# STM32U575 register map
File version: 1.4
CPU: CM33 r0p1, little endian, MPU, FPU, 4 interrupt priority bits
Registers are 32-bit, read-write, reset 0x0 unless marked. A register's access mark holds for its fields unless they carry their own. Offsets are from the block's base; [hi:lo] are bit positions; {n}, {i} and the like mark numbered series; 'fields as' and 'values as' point back to an identical list.

## FMC
Base 0x420D0400
Same registers: SEC_FMC 0x520D0400
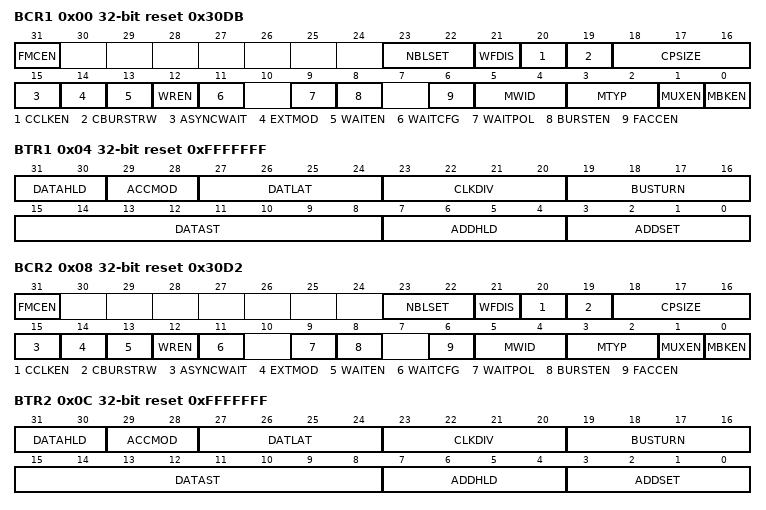
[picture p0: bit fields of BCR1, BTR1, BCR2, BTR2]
0x00 BCR1 reset 0x30DB — SRAM/NOR-Flash chip-select control register for bank 1
  [31] FMCEN — FMC controller enable
  [23:22] NBLSET — Byte lane (NBL) setup
  [21] WFDIS — Write FIFO disable
  [20] CCLKEN — Continuous clock enable
  [19] CBURSTRW — Write burst enable
  [18:16] CPSIZE — CRAM Page Size
  [15] ASYNCWAIT — Wait signal during asynchronous transfers
  [14] EXTMOD — Extended mode enable
  [13] WAITEN — Wait enable bit
  [12] WREN — Write enable bit
  [11] WAITCFG — Wait timing configuration
  [9] WAITPOL — Wait signal polarity bit
  [8] BURSTEN — Burst enable bit
  [6] FACCEN — Flash access enable
  [5:4] MWID — Memory data bus width
  [3:2] MTYP — Memory type
  [1] MUXEN — Address/data multiplexing enable bit
  [0] MBKEN — Memory bank enable bit
0x04 BTR1 reset 0xFFFFFFF — SRAM/NOR-Flash chip-select timing register for bank 1
  [31:30] DATAHLD — Data hold phase duration
  [29:28] ACCMOD — Access mode
  [27:24] DATLAT — Data latency for synchronous memory
  [23:20] CLKDIV — Clock divide ratio (for FMC_CLK signal)
  [19:16] BUSTURN — Bus turnaround phase duration
  [15:8] DATAST — Data-phase duration
  [7:4] ADDHLD — Address-hold phase duration
  [3:0] ADDSET — Address setup phase duration
0x08 BCR2 reset 0x30D2 — SRAM/NOR-Flash chip-select control register for bank 2
  fields as BCR1
0x0C BTR2 reset 0xFFFFFFF — SRAM/NOR-Flash chip-select timing register for bank 2
  fields as BTR1
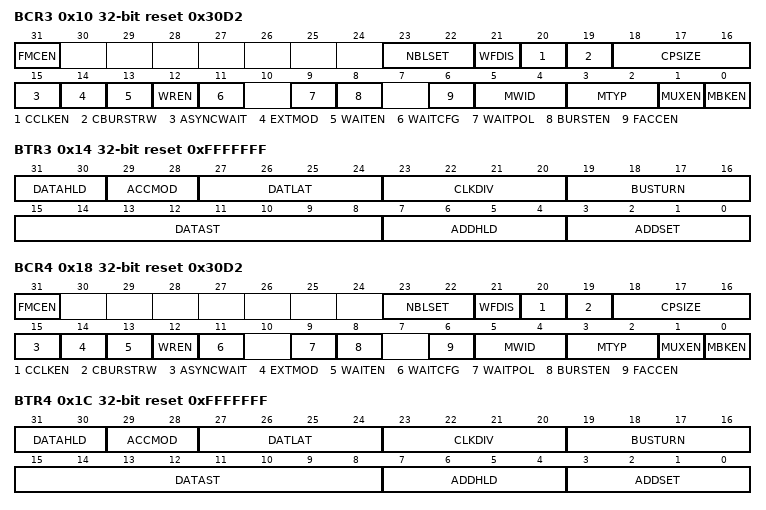
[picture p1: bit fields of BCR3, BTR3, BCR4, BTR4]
0x10 BCR3 reset 0x30D2 — SRAM/NOR-Flash chip-select control register for bank 3
  fields as BCR1
0x14 BTR3 reset 0xFFFFFFF — SRAM/NOR-Flash chip-select timing register for bank 3
  fields as BTR1
0x18 BCR4 reset 0x30D2 — SRAM/NOR-Flash chip-select control register for bank 4
  fields as BCR1
0x1C BTR4 reset 0xFFFFFFF — SRAM/NOR-Flash chip-select timing register for bank 4
  fields as BTR1
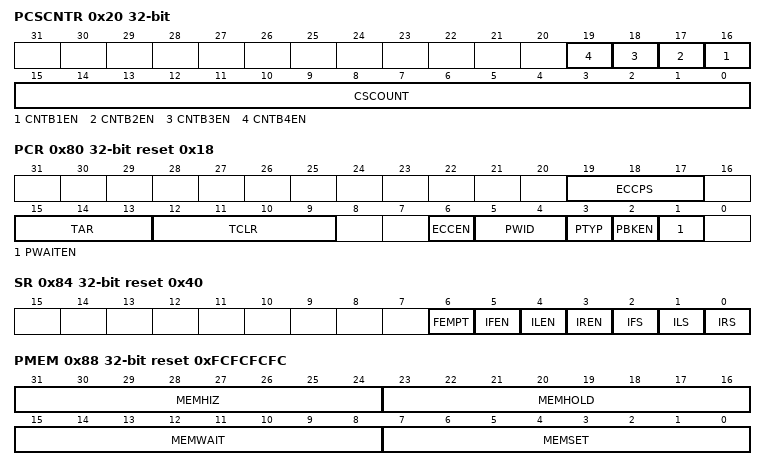
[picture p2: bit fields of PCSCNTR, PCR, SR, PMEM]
0x20 PCSCNTR — PSRAM chip select counter register
  [n+15] CNTB{n}EN (n=1..4) — Counter Bank {n} enable
  [15:0] CSCOUNT — Chip select counter
0x80 PCR reset 0x18 — NAND Flash control registers
  [19:17] ECCPS — ECC page size
  [15:13] TAR — ALE to RE delay
  [12:9] TCLR — CLE to RE delay
  [6] ECCEN — ECC computation logic enable bit
  [5:4] PWID — Data bus width
  [3] PTYP — Memory type
  [2] PBKEN — NAND Flash memory bank enable bit
  [1] PWAITEN — Wait feature enable bit
0x84 SR access per field reset 0x40 — status and interrupt register
  [6] FEMPT ro — FIFO empty. Read-only bit that provides the status of the FIFO
  [5] IFEN rw — Interrupt falling edge detection enable bit
  [4] ILEN rw — Interrupt high-level detection enable bit
  [3] IREN rw — Interrupt rising edge detection enable bit
  [2] IFS rw — Interrupt falling edge status The flag is set by hardware and reset by software. Note: If this bit is written by software to 1 it will be set.
  [1] ILS rw — Interrupt high-level status The flag is set by hardware and reset by software.
  [0] IRS rw — Interrupt rising edge status The flag is set by hardware and reset by software. Note: If this bit is written by software to 1 it will be set.
0x88 PMEM reset 0xFCFCFCFC — Common memory space timing register
  [31:24] MEMHIZ — Common memory x data bus Hi-Z time These bits define the number of KCK_FMC clock cycles during which the data bus is kept Hi-Z after the start of a NAND Flash write access to common memory space. This is only valid for write transactions:
  [23:16] MEMHOLD — Common memory hold time These bits define the number of KCK_FMC clock cycles for write accesses and KCK_FMC+1 clock cycles for read accesses during which the address is held (and data for write accesses) after the command is de-asserted (NWE, NOE), for NAND Flash read or write access to common memory space:
  [15:8] MEMWAIT — Common memory wait time These bits define the minimum number of KCK_FMC (+1) clock cycles to assert the command (NWE, NOE), for NAND Flash read or write access to common memory space. The duration of command assertion is extended if the wait signal (NWAIT) is active (low) at the end of the programmed value of KCK_FMC:
  [7:0] MEMSET — Common memory x setup time These bits define the number of KCK_FMC (+1) clock cycles to set up the address before the command assertion (NWE, NOE), for NAND Flash read or write access to common memory space:
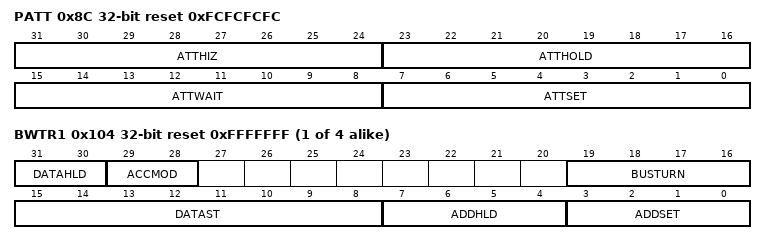
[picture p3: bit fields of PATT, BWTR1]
0x8C PATT reset 0xFCFCFCFC — The FMC_PATT read/write register contains the timing information for NAND Flash memory bank. It is used for 8-bit accesses to the attribute memory space of the NAND Flash for the last address write access if the timing must differ from that of previous accesses (for Ready/Busy management, refer to Section20.8.5: NAND Flash prewait feature).
  [31:24] ATTHIZ — Attribute memory data bus Hi-Z time These bits define the number of KCK_FMC clock cycles during which the data bus is kept in Hi-Z after the start of a NAND Flash write access to attribute memory space on socket. Only valid for writ transaction:
  [23:16] ATTHOLD — Attribute memory hold time These bits define the number of KCK_FMC clock cycles during which the address is held (and data for write access) after the command de-assertion (NWE, NOE), for NAND Flash read or write access to attribute memory space:
  [15:8] ATTWAIT — Attribute memory wait time These bits define the minimum number of x KCK_FMC (+1) clock cycles to assert the command (NWE, NOE), for NAND Flash read or write access to attribute memory space. The duration for command assertion is extended if the wait signal (NWAIT) is active (low) at the end of the programmed value of KCK_FMC:
  [7:0] ATTSET — Attribute memory setup time These bits define the number of KCK_FMC (+1) clock cycles to set up address before the command assertion (NWE, NOE), for NAND Flash read or write access to attribute memory space:
0x94 ECCR ro — This register contain the current error correction code value computed by the ECC computation modules of the FMC NAND controller. When the CPU reads/writes the data from a NAND Flash memory page at the correct address (refer to Section20.8.6: Computation of the error correction code (ECC) in NAND Flash memory), the data read/written from/to the NAND Flash memory are processed automatically by the ECC computation module. When X bytes have been read (according to the ECCPS field in the FMC_PCR registers), the CPU must read the computed ECC value from the FMC_ECC registers. It then verifies if these computed parity data are the same as the parity value recorded in the spare area, to determine whether a page is valid, and, to correct it otherwise. The FMC_ECCR register should be cleared after being read by setting the ECCEN bit to 0. To compute a new data block, the ECCEN bit must be set to 1.
  [31:0] ECC — ECC result This field contains the value computed by the ECC computation logic. Table167 describes the contents of these bit fields.
{0xFC+8i} BWTR{i} reset 0xFFFFFFF (i=1..4) — SRAM/NOR-Flash write timing registers {i}
  [31:30] DATAHLD — Data hold phase duration
  [29:28] ACCMOD — Access mode
  [19:16] BUSTURN — Bus turnaround phase duration
  [15:8] DATAST — Data-phase duration
  [7:4] ADDHLD — Address-hold phase duration
  [3:0] ADDSET — Address setup phase duration
